AUTOSAR XML (schema 4-2-1)
# Copyright (c) 2018 Vector Informatik GmbH.
# License is restricted to the usage with CBD1800257 (D01) for MSR_Vector_SLP4.
# Please contact Vector Informatik whenever you need further information concerning the license conditions.
standard types defined: sint16, uint16, uint8
package /VehicleProject
  system System
package /Cluster
  can cluster CAN00: protocol-name=CAN  # PIHIL
    can physical channel CHNL: comm-connectors=CN_CAN00
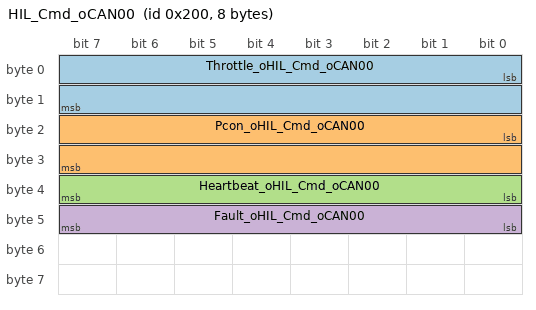
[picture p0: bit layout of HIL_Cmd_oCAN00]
      frame HIL_Cmd_oCAN00: id 0x200, from S32K144, frame-length=8, can-addressing-mode=STANDARD
        pdu HIL_Cmd_oCAN00: length=8, unused-bit-pattern=0
          signal Throttle_oHIL_Cmd_oCAN00: start 0, 16 bit, little-endian, base-type=uint16, compu {phys=raw*0.0001 for raw 0..10000}, transfer-property=PENDING
          signal Pcon_oHIL_Cmd_oCAN00: start 16, 16 bit, little-endian, base-type=uint16, compu {phys=raw*0.001 for raw 0..65534; unit MPa}, unit=MPa, transfer-property=PENDING
          signal Heartbeat_oHIL_Cmd_oCAN00: start 32, 8 bit, little-endian, base-type=uint8, range raw 0..255, transfer-property=PENDING
          signal Fault_oHIL_Cmd_oCAN00: start 40, 8 bit, little-endian, base-type=uint8, range raw 0..255, transfer-property=PENDING
      frame HIL_Vx_oCAN00: id 0x100, to S32K144, frame-length=8, can-addressing-mode=STANDARD
        pdu HIL_Vx_oCAN00: length=8, unused-bit-pattern=0
          signal Vx_oHIL_Vx_oCAN00: start 0, 16 bit, little-endian, base-type=sint16, compu {phys=raw*0.01 for raw 0..32767; unit km/h}, unit=km/h, transfer-property=PENDING, to S32K144
          signal Cnt_oHIL_Vx_oCAN00: start 16, 16 bit, little-endian, base-type=uint16, range raw 0..65535, transfer-property=PENDING, to S32K144
package /ECU
  ecu instance S32K144: associated-com-i-pdu-group=[S32K144_oCAN00_Rx, S32K144_oCAN00_Tx]
    can communication controller CT_CAN00
    can communication connector CN_CAN00: comm-controller=CT_CAN00
package /IPDUGroup
  i signal i pdu group S32K144_oCAN00_Rx: communication-direction=IN, i-signal-i-pdus=HIL_Vx_oCAN00
  i signal i pdu group S32K144_oCAN00_Tx: communication-direction=OUT, i-signal-i-pdus=HIL_Cmd_oCAN00
package /DataType/Unit
  unit U_kmYh: display-name=km/h
  unit U_MPa: display-name=MPa
